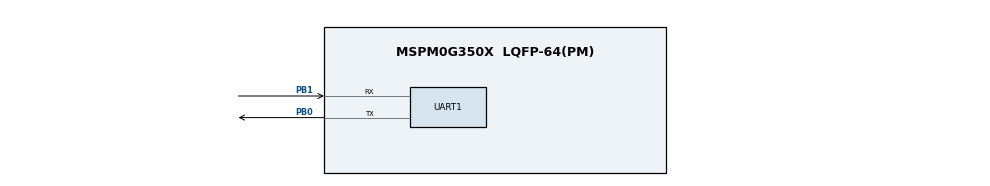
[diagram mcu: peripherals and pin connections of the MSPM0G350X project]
/**
 * @cliArgs --device "MSPM0G350X" --package "LQFP-64(PM)" --part "Default" --product "mspm0_sdk@1.30.00.03"
 * @versions {"tool":"1.19.0+3426"}
 */

/**
 * Import the modules used in this configuration.
 */
const ADC12  = scripting.addModule("/ti/driverlib/ADC12", {}, false);
const ADC121 = ADC12.addInstance();
const Board  = scripting.addModule("/ti/driverlib/Board");
const SYSCTL = scripting.addModule("/ti/driverlib/SYSCTL");
const UART   = scripting.addModule("/ti/driverlib/UART", {}, false);
const UART1  = UART.addInstance();

/**
 * Write custom configuration values to the imported modules.
 */
ADC121.$name                      = "ADC12_0";
ADC121.sampClkSrc                 = "DL_ADC12_CLOCK_ULPCLK";
ADC121.sampClkDiv                 = "DL_ADC12_CLOCK_DIVIDE_8";
ADC121.adcMem0chansel             = "DL_ADC12_INPUT_CHAN_2";
ADC121.sampleTime0                = "125 us";
ADC121.enabledInterrupts          = ["DL_ADC12_INTERRUPT_MEM0_RESULT_LOADED"];
ADC121.powerDownMode              = "DL_ADC12_POWER_DOWN_MODE_MANUAL";
ADC121.peripheral.$assign         = "ADC0";
ADC121.peripheral.adcPin2.$assign = "PA25";
ADC121.adcPin2Config.$name        = "ti_driverlib_gpio_GPIOPinGeneric0";


SYSCTL.forceDefaultClkConfig = true;
SYSCTL.MFPCLKEn              = true;
SYSCTL.peripheral.$assign    = "SYSCTL";

UART1.$name                    = "UART_0";
UART1.enableFIFO               = true;
UART1.rxFifoThreshold          = "DL_UART_RX_FIFO_LEVEL_ONE_ENTRY";
UART1.txFifoThreshold          = "DL_UART_TX_FIFO_LEVEL_3_4_EMPTY";
UART1.analogGlitchFilter       = "DL_UART_PULSE_WIDTH_10_NS";
UART1.peripheral.$assign       = "UART0";
UART1.peripheral.rxPin.$assign = "PB1";
UART1.peripheral.txPin.$assign = "PB0";
UART1.txPinConfig.$name        = "ti_driverlib_gpio_GPIOPinGeneric1";
UART1.rxPinConfig.$name        = "ti_driverlib_gpio_GPIOPinGeneric2";

/**
 * Pinmux solution for unlocked pins/peripherals. This ensures that minor changes to the automatic solver in a future
 * version of the tool will not impact the pinmux you originally saw.  These lines can be completely deleted in order to
 * re-solve from scratch.
 */
Board.peripheral.$suggestSolution          = "DEBUGSS";
Board.peripheral.swclkPin.$suggestSolution = "PA20";
Board.peripheral.swdioPin.$suggestSolution = "PA19";
